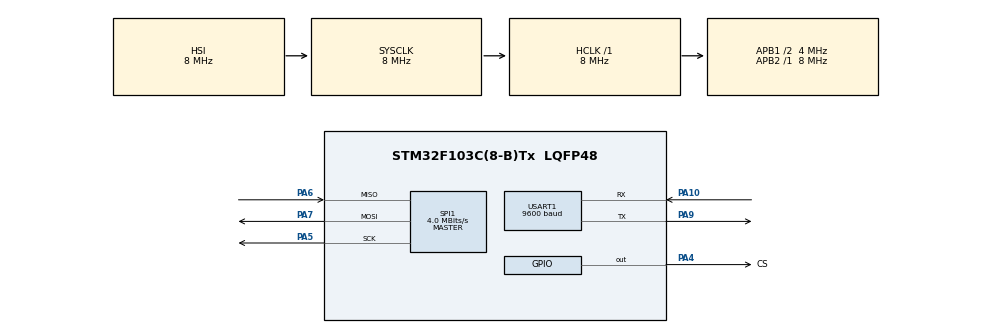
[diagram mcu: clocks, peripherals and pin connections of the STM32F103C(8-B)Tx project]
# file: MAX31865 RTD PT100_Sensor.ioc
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Mcu.Family=STM32F1
Mcu.Name=STM32F103C(8-B)Tx
Mcu.Package=LQFP48
NVIC.PriorityGroup=NVIC_PRIORITYGROUP_4
PA10.Mode=Asynchronous
PA10.Signal=USART1_RX
PA13.Mode=Serial_Wire
PA13.Signal=SYS_JTMS-SWDIO
PA14.Mode=Serial_Wire
PA14.Signal=SYS_JTCK-SWCLK
PA4.GPIO_Label=CS
PA4.Signal=GPIO_Output
PA5.Mode=Full_Duplex_Master
PA5.Signal=SPI1_SCK
PA6.Mode=Full_Duplex_Master
PA6.Signal=SPI1_MISO
PA7.Mode=Full_Duplex_Master
PA7.Signal=SPI1_MOSI
PA9.Mode=Asynchronous
PA9.Signal=USART1_TX
PD0-OSC_IN.Mode=HSE-External-Oscillator
PD0-OSC_IN.Signal=RCC_OSC_IN
PD1-OSC_OUT.Mode=HSE-External-Oscillator
PD1-OSC_OUT.Signal=RCC_OSC_OUT
ProjectManager.HeapSize=0x200
ProjectManager.StackSize=0x400
ProjectManager.TargetToolchain=STM32CubeIDE
RCC.AHBFreq_Value=8000000
RCC.APB1CLKDivider=RCC_HCLK_DIV2
RCC.APB1Freq_Value=4000000
RCC.APB1TimFreq_Value=8000000
RCC.APB2Freq_Value=8000000
RCC.APB2TimFreq_Value=8000000
RCC.HCLKFreq_Value=8000000
RCC.PLLMUL=RCC_PLL_MUL9
RCC.PLLSourceVirtual=RCC_PLLSOURCE_HSE
RCC.SYSCLKFreq_VALUE=8000000
RCC.USBFreq_Value=72000000
SPI1.BaudRatePrescaler=SPI_BAUDRATEPRESCALER_2
SPI1.CLKPhase=SPI_PHASE_2EDGE
SPI1.CalculateBaudRate=4.0 MBits/s
SPI1.Direction=SPI_DIRECTION_2LINES
SPI1.Mode=SPI_MODE_MASTER
SPI1.VirtualType=VM_MASTER
USART1.BaudRate=9600
USART1.VirtualMode=VM_ASYNC
board=custom

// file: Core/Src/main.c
/* USER CODE BEGIN Header */
/**
  ******************************************************************************
  * @file           : main.c
  * @brief          : Main program body
  ******************************************************************************
  * @attention
  *
  * Copyright (c) 2024 STMicroelectronics.
  * All rights reserved.
  *
  * This software is licensed under terms that can be found in the LICENSE file
  * in the root directory of this software component.
  * If no LICENSE file comes with this software, it is provided AS-IS.
  *
  ******************************************************************************
  */
/* USER CODE END Header */
#include "main.h"

/* USER CODE BEGIN Includes */

#include "MAX31865.h"
#include<stdio.h>
#include<string.h>

/* USER CODE END Includes */

/* USER CODE BEGIN PD */

#define RREF      430.0
#define RNOMINAL  100.0

/* USER CODE END PD */

SPI_HandleTypeDef hspi1;

UART_HandleTypeDef huart1;

void SystemClock_Config(void);
static void MX_GPIO_Init(void);
static void MX_SPI1_Init(void);
static void MX_USART1_UART_Init(void);

int main(void)
{

  /* USER CODE BEGIN 1 */

	uint16_t rtd = 0;
	uint8_t fault;
	max31865_fault_cycle_t fault_cycle = MAX31865_FAULT_AUTO;
	float ratio;
	char MSG1[20];
	char buffer[50]; // Adjust the size according to your needs

  /* USER CODE END 1 */

  /* MCU Configuration--------------------------------------------------------*/

  /* Reset of all peripherals, Initializes the Flash interface and the Systick. */
  HAL_Init();

  /* Configure the system clock */
  SystemClock_Config();

  /* Initialize all configured peripherals */
  MX_GPIO_Init();
  MX_SPI1_Init();
  MX_USART1_UART_Init();
  /* USER CODE BEGIN 2 */

   begin(MAX31865_4WIRE);  // set to 2WIRE or 4WIRE as necessary

  /* USER CODE END 2 */

  /* Infinite loop */
  while (1)
  {
	  	  rtd = readRTD();
	      ratio = rtd;
	      ratio /= 32768;

	      sprintf(MSG1,"RTD value: %d",rtd);
	      HAL_UART_Transmit(&huart1,(uint8_t*) MSG1, sizeof(MSG1), 100);
	      HAL_UART_Transmit(&huart1,(uint8_t*) "\n\r",2, 10);

	      sprintf(MSG1,"Ratio = %.8f" ,ratio);
	      HAL_UART_Transmit(&huart1,(uint8_t*) MSG1, sizeof(MSG1), 100);
	      HAL_UART_Transmit(&huart1,(uint8_t*) "\n\r",2, 10);

	      sprintf(MSG1,"Resistance = %.8f",RREF*ratio);
	      HAL_UART_Transmit(&huart1,(uint8_t*) MSG1, sizeof(MSG1), 100);
	      HAL_UART_Transmit(&huart1,(uint8_t*) "\n\r",2, 10);

	      sprintf(MSG1,"Temperature = %.2f",temperature(RNOMINAL, RREF));
	      HAL_UART_Transmit(&huart1,(uint8_t*) "***********", 10, 50);
	      HAL_UART_Transmit(&huart1,(uint8_t*) MSG1, sizeof(MSG1), 100);
	      HAL_UART_Transmit(&huart1,(uint8_t*) "************", 10, 50);
	      HAL_UART_Transmit(&huart1,(uint8_t*) "\n\r",2, 10);

	      fault = readFault(fault_cycle);
	      if (fault) {
	           sprintf(buffer, "Fault 0x%X\n", fault);
	           HAL_UART_Transmit(&huart1, (uint8_t*)buffer, strlen(buffer), HAL_MAX_DELAY);

	           if (fault & MAX31865_FAULT_HIGHTHRESH) {
	               sprintf(buffer, "RTD High Threshold\n");
	               HAL_UART_Transmit(&huart1, (uint8_t*)buffer, strlen(buffer), HAL_MAX_DELAY);
	           }
	           if (fault & MAX31865_FAULT_LOWTHRESH) {
	               sprintf(buffer, "RTD Low Threshold\n");
	               HAL_UART_Transmit(&huart1, (uint8_t*)buffer, strlen(buffer), HAL_MAX_DELAY);
	           }
	           if (fault & MAX31865_FAULT_REFINLOW) {
	               sprintf(buffer, "REFIN- > 0.85 x Bias\n");
	               HAL_UART_Transmit(&huart1, (uint8_t*)buffer, strlen(buffer), HAL_MAX_DELAY);
	           }
	           if (fault & MAX31865_FAULT_REFINHIGH) {
	               sprintf(buffer, "REFIN- < 0.85 x Bias - FORCE- open\n");
	               HAL_UART_Transmit(&huart1, (uint8_t*)buffer, strlen(buffer), HAL_MAX_DELAY);
	           }
	           if (fault & MAX31865_FAULT_RTDINLOW) {
	               sprintf(buffer, "RTDIN- < 0.85 x Bias - FORCE- open\n");
	               HAL_UART_Transmit(&huart1, (uint8_t*)buffer, strlen(buffer), HAL_MAX_DELAY);
	           }
	           if (fault & MAX31865_FAULT_OVUV) {
	               sprintf(buffer, "Under/Over voltage\n");
	               HAL_UART_Transmit(&huart1, (uint8_t*)buffer, strlen(buffer), HAL_MAX_DELAY);
	           }
	           clearFault();
	       }
	       HAL_Delay(5000);
	      }
  }

void SystemClock_Config(void)
{
  RCC_OscInitTypeDef RCC_OscInitStruct = {0};
  RCC_ClkInitTypeDef RCC_ClkInitStruct = {0};

  /** Initializes the RCC Oscillators according to the specified parameters
  * in the RCC_OscInitTypeDef structure.
  */
  RCC_OscInitStruct.OscillatorType = RCC_OSCILLATORTYPE_HSI;
  RCC_OscInitStruct.HSIState = RCC_HSI_ON;
  RCC_OscInitStruct.HSICalibrationValue = RCC_HSICALIBRATION_DEFAULT;
  RCC_OscInitStruct.PLL.PLLState = RCC_PLL_NONE;
  if (HAL_RCC_OscConfig(&RCC_OscInitStruct) != HAL_OK)
  {
    Error_Handler();
  }

  /** Initializes the CPU, AHB and APB buses clocks
  */
  RCC_ClkInitStruct.ClockType = RCC_CLOCKTYPE_HCLK|RCC_CLOCKTYPE_SYSCLK
                              |RCC_CLOCKTYPE_PCLK1|RCC_CLOCKTYPE_PCLK2;
  RCC_ClkInitStruct.SYSCLKSource = RCC_SYSCLKSOURCE_HSI;
  RCC_ClkInitStruct.AHBCLKDivider = RCC_SYSCLK_DIV1;
  RCC_ClkInitStruct.APB1CLKDivider = RCC_HCLK_DIV2;
  RCC_ClkInitStruct.APB2CLKDivider = RCC_HCLK_DIV1;

  if (HAL_RCC_ClockConfig(&RCC_ClkInitStruct, FLASH_LATENCY_0) != HAL_OK)
  {
    Error_Handler();
  }
}

static void MX_SPI1_Init(void)
{

  /* SPI1 parameter configuration*/
  hspi1.Instance = SPI1;
  hspi1.Init.Mode = SPI_MODE_MASTER;
  hspi1.Init.Direction = SPI_DIRECTION_2LINES;
  hspi1.Init.DataSize = SPI_DATASIZE_8BIT;
  hspi1.Init.CLKPolarity = SPI_POLARITY_LOW;
  hspi1.Init.CLKPhase = SPI_PHASE_2EDGE;
  hspi1.Init.NSS = SPI_NSS_SOFT;
  hspi1.Init.BaudRatePrescaler = SPI_BAUDRATEPRESCALER_2;
  hspi1.Init.FirstBit = SPI_FIRSTBIT_MSB;
  hspi1.Init.TIMode = SPI_TIMODE_DISABLE;
  hspi1.Init.CRCCalculation = SPI_CRCCALCULATION_DISABLE;
  hspi1.Init.CRCPolynomial = 10;
  if (HAL_SPI_Init(&hspi1) != HAL_OK)
  {
    Error_Handler();
  }

}

static void MX_USART1_UART_Init(void)
{

  huart1.Instance = USART1;
  huart1.Init.BaudRate = 9600;
  huart1.Init.WordLength = UART_WORDLENGTH_8B;
  huart1.Init.StopBits = UART_STOPBITS_1;
  huart1.Init.Parity = UART_PARITY_NONE;
  huart1.Init.Mode = UART_MODE_TX_RX;
  huart1.Init.HwFlowCtl = UART_HWCONTROL_NONE;
  huart1.Init.OverSampling = UART_OVERSAMPLING_16;
  if (HAL_UART_Init(&huart1) != HAL_OK)
  {
    Error_Handler();
  }

}

static void MX_GPIO_Init(void)
{
  GPIO_InitTypeDef GPIO_InitStruct = {0};

  /* GPIO Ports Clock Enable */
  __HAL_RCC_GPIOD_CLK_ENABLE();
  __HAL_RCC_GPIOA_CLK_ENABLE();

  /*Configure GPIO pin Output Level */
  HAL_GPIO_WritePin(CS_GPIO_Port, CS_Pin, GPIO_PIN_RESET);

  /*Configure GPIO pin : CS_Pin */
  GPIO_InitStruct.Pin = CS_Pin;
  GPIO_InitStruct.Mode = GPIO_MODE_OUTPUT_PP;
  GPIO_InitStruct.Pull = GPIO_NOPULL;
  GPIO_InitStruct.Speed = GPIO_SPEED_FREQ_LOW;
  HAL_GPIO_Init(CS_GPIO_Port, &GPIO_InitStruct);

}

void Error_Handler(void)
{
  __disable_irq();
  while (1)
  {
  }
}
